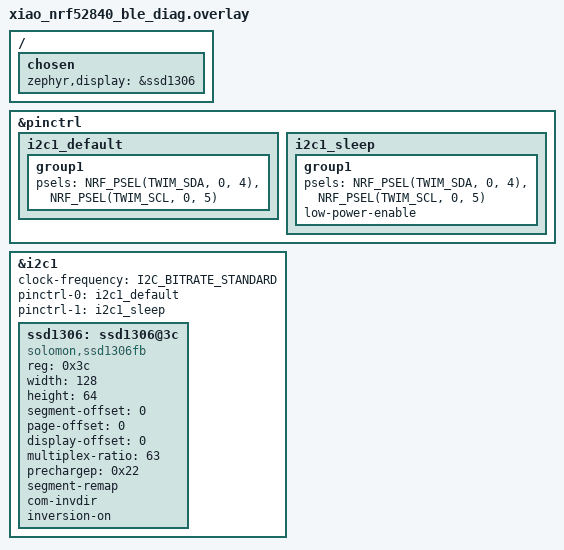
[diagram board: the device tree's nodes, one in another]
/* XIAO nRF52840 BLE diag + SSD1306 */

#include <dt-bindings/pinctrl/nrf-pinctrl.h>

&pinctrl {
	i2c1_default: i2c1_default {
 		group1 {
			psels = <NRF_PSEL(TWIM_SDA, 0, 4)>,
				<NRF_PSEL(TWIM_SCL, 0, 5)>;
 		};
 	};
 	i2c1_sleep: i2c1_sleep {
 		group1 {
			psels = <NRF_PSEL(TWIM_SDA, 0, 4)>,
				<NRF_PSEL(TWIM_SCL, 0, 5)>;
			low-power-enable;
		};
	};
};

&i2c1 {
	status = "okay";
	clock-frequency = <I2C_BITRATE_STANDARD>;
	pinctrl-0 = <&i2c1_default>;
	pinctrl-1 = <&i2c1_sleep>;
	pinctrl-names = "default", "sleep";

	ssd1306: ssd1306@3c {
		compatible = "solomon,ssd1306fb";
		reg = <0x3c>;
		width = <128>;
		height = <64>;
		segment-offset = <0>;
		page-offset = <0>;
		display-offset = <0>;
		multiplex-ratio = <63>;
		prechargep = <0x22>;
		segment-remap;
		com-invdir;
		inversion-on;
		status = "okay";
	};
};

/ {
	chosen {
		zephyr,display = &ssd1306;
	};
};
